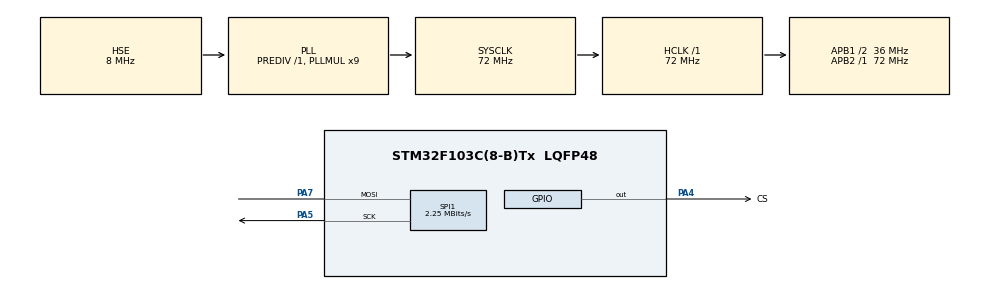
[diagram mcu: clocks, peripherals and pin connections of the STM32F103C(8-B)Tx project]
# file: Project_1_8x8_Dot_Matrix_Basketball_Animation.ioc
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Mcu.Family=STM32F1
Mcu.Name=STM32F103C(8-B)Tx
Mcu.Package=LQFP48
NVIC.PriorityGroup=NVIC_PRIORITYGROUP_4
PA4.GPIO_Label=CS
PA4.Signal=GPIO_Output
PA5.Mode=Simplex_Bidirectional_Master
PA5.Signal=SPI1_SCK
PA7.Mode=Simplex_Bidirectional_Master
PA7.Signal=SPI1_MOSI
PD0-OSC_IN.Mode=HSE-External-Oscillator
PD0-OSC_IN.Signal=RCC_OSC_IN
PD1-OSC_OUT.Mode=HSE-External-Oscillator
PD1-OSC_OUT.Signal=RCC_OSC_OUT
ProjectManager.HeapSize=0x200
ProjectManager.StackSize=0x400
ProjectManager.TargetToolchain=STM32CubeIDE
RCC.AHBFreq_Value=72000000
RCC.APB1CLKDivider=RCC_HCLK_DIV2
RCC.APB1Freq_Value=36000000
RCC.APB1TimFreq_Value=72000000
RCC.APB2Freq_Value=72000000
RCC.APB2TimFreq_Value=72000000
RCC.HCLKFreq_Value=72000000
RCC.PLLMUL=RCC_PLL_MUL9
RCC.PLLSourceVirtual=RCC_PLLSOURCE_HSE
RCC.SYSCLKFreq_VALUE=72000000
RCC.SYSCLKSource=RCC_SYSCLKSOURCE_PLLCLK
RCC.USBFreq_Value=72000000
SPI1.BaudRatePrescaler=SPI_BAUDRATEPRESCALER_32
SPI1.CLKPolarity=SPI_POLARITY_HIGH
SPI1.CalculateBaudRate=2.25 MBits/s
SPI1.DataSize=SPI_DATASIZE_16BIT
SPI1.Direction=SPI_DIRECTION_1LINE
SPI1.Mode=SPI_MODE_MASTER
SPI1.VirtualType=VM_MASTER
VP_SYS_VS_ND.Mode=No_Debug
board=custom

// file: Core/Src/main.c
/* USER CODE BEGIN Header */
/**
  ******************************************************************************
  * @file           : main.c
  * @brief          : Main program body
  ******************************************************************************
  * @attention
  *
  * Copyright (c) 2024 STMicroelectronics.
  * All rights reserved.
  *
  * This software is licensed under terms that can be found in the LICENSE file
  * in the root directory of this software component.
  * If no LICENSE file comes with this software, it is provided AS-IS.
  *
  ******************************************************************************
  */
/* USER CODE END Header */
#include "main.h"

SPI_HandleTypeDef hspi1;

/* USER CODE BEGIN PV */
const uint8_t charData[][8] = {
		{0x01, 0x01, 0x01, 0x07, 0x81, 0xc1, 0x81, 0xa1},  // The ball is on the ground.
		{0x01, 0x01, 0x01, 0x07, 0x41, 0x81, 0xc1, 0xa1},  // The man leaned to the ball.
		{0x01, 0x01, 0x01, 0x07, 0x81, 0xc1, 0xa1, 0x81},  // The ball has been lifted 1.
		{0x01, 0x01, 0x01, 0x07, 0x81, 0xc1, 0xa1, 0x81},  // The ball has been lifted 2.
		{0x01, 0x01, 0x01, 0x07, 0xa1, 0xc1, 0x81, 0x81},  // The ball was thrown by the man 1.
		{0x01, 0x01, 0x01, 0x17, 0x81, 0xc1, 0x81, 0x81},  // The ball was thrown by the man 2.
		{0x01, 0x01, 0x09, 0x07, 0x81, 0xc1, 0x81, 0x81},  // The ball was thrown by the man 3.
		{0x01, 0x05, 0x01, 0x07, 0x81, 0xc1, 0x81, 0x81},  // The ball was thrown by the man 4.
		{0x01, 0x03, 0x01, 0x07, 0x81, 0xc1, 0x81, 0x81},  // The ball was thrown by the man 5.
		{0x01, 0x01, 0x03, 0x07, 0x81, 0xc1, 0x81, 0x81},  // The ball hit the basket.
		{0x01, 0x01, 0x01, 0x07, 0x81, 0xc1, 0x81, 0x81},  // The ball is in the basket.
		{0x01, 0x01, 0x01, 0x07, 0x83, 0xc1, 0x81, 0x81},  // The ball falls from the basket 3 meter.
		{0x01, 0x01, 0x01, 0x07, 0x81, 0xc3, 0x81, 0x81},  // The ball falls from the basket 2 meter.
		{0x01, 0x01, 0x01, 0x07, 0x81, 0xc1, 0x83, 0x81},  // The ball falls from the basket 1 meter.
		{0x01, 0x01, 0x01, 0x07, 0x81, 0xc1, 0x81, 0x83},  // The ball falls from the basket 0 meter.
		{0x01, 0x01, 0x01, 0x07, 0x81, 0xc1, 0x81, 0x85},  // The ball rolled 1 meter.
		{0x01, 0x01, 0x01, 0x07, 0x81, 0xc1, 0x81, 0x89},  // The ball rolled 2 meter.
		{0x01, 0x01, 0x01, 0x07, 0x81, 0xc1, 0x81, 0x91},  // The ball rolled 3 meter.
		{0x01, 0x01, 0x01, 0x07, 0x81, 0xc1, 0x81, 0xa1}   // The ball is in its original position.
};
/* USER CODE END PV */

void SystemClock_Config(void);
static void MX_GPIO_Init(void);
static void MX_SPI1_Init(void);

/* USER CODE BEGIN 0 */
void max7219_write (uint8_t Addr, uint8_t data)
{
	uint16_t writeData = (Addr<<8)|data;
	HAL_GPIO_WritePin(CS_GPIO_Port, CS_Pin, 0);  // enable slave
	HAL_SPI_Transmit(&hspi1, (uint8_t *)&writeData, 1, 100);
	HAL_GPIO_WritePin(CS_GPIO_Port, CS_Pin, 1);  // disable slave
}

void matrixInit (void)
{
	max7219_write(0x09, 0);  // no decoding
	max7219_write(0x0a, 0x01);  // 3/32 intensity
	max7219_write(0x0B, 0x07);  // scan all 7 columns
	max7219_write(0x0C, 0x01);  // normal operation
	max7219_write(0x0F, 0);     // No display test
}

void matrixData(int num)
{
	for (int i=1; i<=8; i++)
	{
		max7219_write(i, charData[num][8-i]);
	}
}

/* USER CODE END 0 */

int main(void)
{

  /* MCU Configuration--------------------------------------------------------*/

  /* Reset of all peripherals, Initializes the Flash interface and the Systick. */
  HAL_Init();

  /* Configure the system clock */
  SystemClock_Config();

  /* Initialize all configured peripherals */
  MX_GPIO_Init();
  MX_SPI1_Init();
  /* USER CODE BEGIN 2 */

  matrixInit();

  /* USER CODE END 2 */

  /* Infinite loop */
  while (1)
  {

    /* USER CODE BEGIN 3 */
	    for (int i=0; i<19; i++)
	    {
	      matrixData(i);
	      HAL_Delay(100);
	    }
	    HAL_Delay(1000);
  }
  /* USER CODE END 3 */
}

void SystemClock_Config(void)
{
  RCC_OscInitTypeDef RCC_OscInitStruct = {0};
  RCC_ClkInitTypeDef RCC_ClkInitStruct = {0};

  /** Initializes the RCC Oscillators according to the specified parameters
  * in the RCC_OscInitTypeDef structure.
  */
  RCC_OscInitStruct.OscillatorType = RCC_OSCILLATORTYPE_HSE;
  RCC_OscInitStruct.HSEState = RCC_HSE_ON;
  RCC_OscInitStruct.HSEPredivValue = RCC_HSE_PREDIV_DIV1;
  RCC_OscInitStruct.HSIState = RCC_HSI_ON;
  RCC_OscInitStruct.PLL.PLLState = RCC_PLL_ON;
  RCC_OscInitStruct.PLL.PLLSource = RCC_PLLSOURCE_HSE;
  RCC_OscInitStruct.PLL.PLLMUL = RCC_PLL_MUL9;
  if (HAL_RCC_OscConfig(&RCC_OscInitStruct) != HAL_OK)
  {
    Error_Handler();
  }

  /** Initializes the CPU, AHB and APB buses clocks
  */
  RCC_ClkInitStruct.ClockType = RCC_CLOCKTYPE_HCLK|RCC_CLOCKTYPE_SYSCLK
                              |RCC_CLOCKTYPE_PCLK1|RCC_CLOCKTYPE_PCLK2;
  RCC_ClkInitStruct.SYSCLKSource = RCC_SYSCLKSOURCE_PLLCLK;
  RCC_ClkInitStruct.AHBCLKDivider = RCC_SYSCLK_DIV1;
  RCC_ClkInitStruct.APB1CLKDivider = RCC_HCLK_DIV2;
  RCC_ClkInitStruct.APB2CLKDivider = RCC_HCLK_DIV1;

  if (HAL_RCC_ClockConfig(&RCC_ClkInitStruct, FLASH_LATENCY_2) != HAL_OK)
  {
    Error_Handler();
  }
}

static void MX_SPI1_Init(void)
{

  /* SPI1 parameter configuration*/
  hspi1.Instance = SPI1;
  hspi1.Init.Mode = SPI_MODE_MASTER;
  hspi1.Init.Direction = SPI_DIRECTION_1LINE;
  hspi1.Init.DataSize = SPI_DATASIZE_16BIT;
  hspi1.Init.CLKPolarity = SPI_POLARITY_HIGH;
  hspi1.Init.CLKPhase = SPI_PHASE_1EDGE;
  hspi1.Init.NSS = SPI_NSS_SOFT;
  hspi1.Init.BaudRatePrescaler = SPI_BAUDRATEPRESCALER_32;
  hspi1.Init.FirstBit = SPI_FIRSTBIT_MSB;
  hspi1.Init.TIMode = SPI_TIMODE_DISABLE;
  hspi1.Init.CRCCalculation = SPI_CRCCALCULATION_DISABLE;
  hspi1.Init.CRCPolynomial = 10;
  if (HAL_SPI_Init(&hspi1) != HAL_OK)
  {
    Error_Handler();
  }

}

static void MX_GPIO_Init(void)
{
  GPIO_InitTypeDef GPIO_InitStruct = {0};

  /* GPIO Ports Clock Enable */
  __HAL_RCC_GPIOD_CLK_ENABLE();
  __HAL_RCC_GPIOA_CLK_ENABLE();

  /*Configure GPIO pin Output Level */
  HAL_GPIO_WritePin(CS_GPIO_Port, CS_Pin, GPIO_PIN_RESET);

  /*Configure GPIO pin : CS_Pin */
  GPIO_InitStruct.Pin = CS_Pin;
  GPIO_InitStruct.Mode = GPIO_MODE_OUTPUT_PP;
  GPIO_InitStruct.Pull = GPIO_NOPULL;
  GPIO_InitStruct.Speed = GPIO_SPEED_FREQ_LOW;
  HAL_GPIO_Init(CS_GPIO_Port, &GPIO_InitStruct);

}

void Error_Handler(void)
{
  __disable_irq();
  while (1)
  {
  }
}
